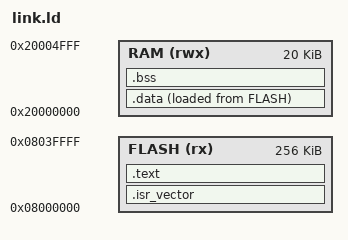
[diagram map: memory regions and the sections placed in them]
/* Bare-metal STM32F105RC: 256K flash. RAM top matches the emulator's
 * default F105 mapping (20K at 0x20000000, like Arduino's own F105RC
 * linkscripts) so the image also boots with default chip sizes. */
_estack = 0x20005000;

MEMORY {
    FLASH (rx)  : ORIGIN = 0x08000000, LENGTH = 256K
    RAM (rwx)   : ORIGIN = 0x20000000, LENGTH = 20K
}

SECTIONS {
    .isr_vector : {
        KEEP(*(.isr_vector))
    } > FLASH

    .text : {
        *(.text*)
        *(.rodata*)
    } > FLASH

    .data : {
        _sdata = .;
        *(.data*)
        _edata = .;
    } > RAM AT > FLASH
    _sidata = LOADADDR(.data);

    .bss : {
        _sbss = .;
        *(.bss*)
        *(COMMON)
        _ebss = .;
    } > RAM
}
